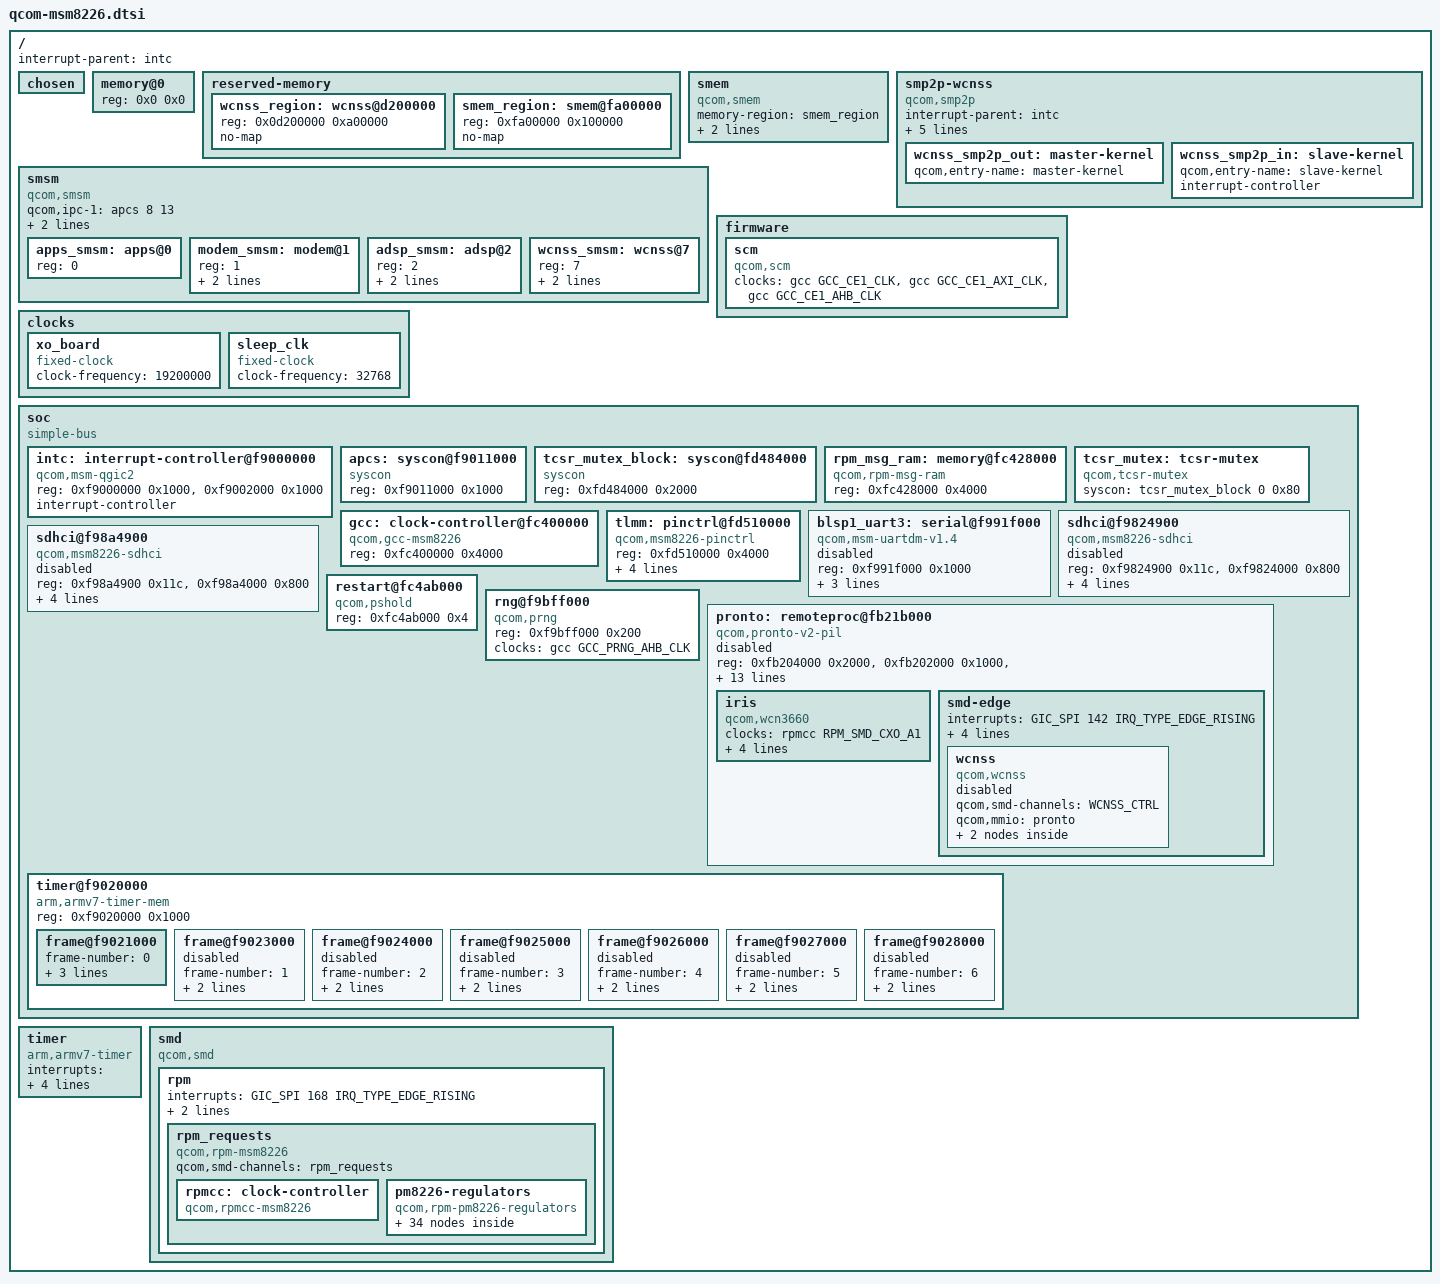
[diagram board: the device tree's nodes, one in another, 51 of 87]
// SPDX-License-Identifier: BSD-3-Clause
/*
 * Copyright (c) 2020, The Linux Foundation. All rights reserved.
 */

/dts-v1/;

#include <dt-bindings/interrupt-controller/arm-gic.h>
#include <dt-bindings/clock/qcom,gcc-msm8974.h>
#include <dt-bindings/clock/qcom,rpmcc.h>
#include <dt-bindings/gpio/gpio.h>

/ {
	#address-cells = <1>;
	#size-cells = <1>;
	interrupt-parent = <&intc>;

	chosen { };

	memory@0 {
		device_type = "memory";
		reg = <0x0 0x0>;
	};

	reserved-memory {
		#address-cells = <1>;
		#size-cells = <1>;
		ranges;

		wcnss_region: wcnss@d200000 {
			reg = <0x0d200000 0xa00000>;
			no-map;
		};

		smem_region: smem@fa00000 {
			reg = <0xfa00000 0x100000>;
			no-map;
		};
	};

	smem {
		compatible = "qcom,smem";

		memory-region = <&smem_region>;
		qcom,rpm-msg-ram = <&rpm_msg_ram>;

		hwlocks = <&tcsr_mutex 3>;
	};

	smp2p-wcnss {
		compatible = "qcom,smp2p";

		interrupt-parent = <&intc>;
		interrupts = <GIC_SPI 143 IRQ_TYPE_EDGE_RISING>;

		qcom,smem = <451>, <431>;
		qcom,ipc = <&apcs 8 18>;
		qcom,local-pid = <0>;
		qcom,remote-pid = <4>;

		wcnss_smp2p_out: master-kernel {
			qcom,entry-name = "master-kernel";

			#qcom,smem-state-cells = <1>;
		};

		wcnss_smp2p_in: slave-kernel {
			qcom,entry-name = "slave-kernel";

			interrupt-controller;
			#interrupt-cells = <2>;
		};
	};

	smsm {
		compatible = "qcom,smsm";

		#address-cells = <1>;
		#size-cells = <0>;

		qcom,ipc-1 = <&apcs 8 13>;
		qcom,ipc-2 = <&apcs 8 9>;
		qcom,ipc-3 = <&apcs 8 19>;

		apps_smsm: apps@0 {
			reg = <0>;

			#qcom,smem-state-cells = <1>;
		};

		modem_smsm: modem@1 {
			reg = <1>;
			interrupts = <GIC_SPI 26 IRQ_TYPE_EDGE_RISING>;

			interrupt-controller;
			#interrupt-cells = <2>;
		};

		adsp_smsm: adsp@2 {
			reg = <2>;
			interrupts = <GIC_SPI 157 IRQ_TYPE_EDGE_RISING>;

			interrupt-controller;
			#interrupt-cells = <2>;
		};

		wcnss_smsm: wcnss@7 {
			reg = <7>;
			interrupts = <GIC_SPI 144 IRQ_TYPE_EDGE_RISING>;

			interrupt-controller;
			#interrupt-cells = <2>;
		};
	};

	firmware {
		scm {
			compatible = "qcom,scm";
			clocks = <&gcc GCC_CE1_CLK>, <&gcc GCC_CE1_AXI_CLK>, <&gcc GCC_CE1_AHB_CLK>;
			clock-names = "core", "bus", "iface";
		};
	};

	clocks {
		xo_board: xo_board {
			compatible = "fixed-clock";
			#clock-cells = <0>;
			clock-frequency = <19200000>;
		};

		sleep_clk: sleep_clk {
			compatible = "fixed-clock";
			#clock-cells = <0>;
			clock-frequency = <32768>;
		};
	};

	soc: soc {
		compatible = "simple-bus";
		#address-cells = <1>;
		#size-cells = <1>;
		ranges;

		intc: interrupt-controller@f9000000 {
			compatible = "qcom,msm-qgic2";
			reg = <0xf9000000 0x1000>,
			      <0xf9002000 0x1000>;
			interrupt-controller;
			#interrupt-cells = <3>;
		};

		apcs: syscon@f9011000 {
			compatible = "syscon";
			reg = <0xf9011000 0x1000>;
		};

		tcsr_mutex_block: syscon@fd484000 {
			compatible = "syscon";
			reg = <0xfd484000 0x2000>;
		};

		rpm_msg_ram: memory@fc428000 {
			compatible = "qcom,rpm-msg-ram";
			reg = <0xfc428000 0x4000>;
		};

		tcsr_mutex: tcsr-mutex {
			compatible = "qcom,tcsr-mutex";
			syscon = <&tcsr_mutex_block 0 0x80>;

			#hwlock-cells = <1>;
		};

		gcc: clock-controller@fc400000 {
			compatible = "qcom,gcc-msm8226";
			reg = <0xfc400000 0x4000>;
			#clock-cells = <1>;
			#reset-cells = <1>;
			#power-domain-cells = <1>;
		};

		tlmm: pinctrl@fd510000 {
			compatible = "qcom,msm8226-pinctrl";
			reg = <0xfd510000 0x4000>;
			gpio-controller;
			#gpio-cells = <2>;
			gpio-ranges = <&tlmm 0 0 117>;
			interrupt-controller;
			#interrupt-cells = <2>;
			interrupts = <GIC_SPI 208 IRQ_TYPE_LEVEL_HIGH>;
		};

		blsp1_uart3: serial@f991f000 {
			compatible = "qcom,msm-uartdm-v1.4", "qcom,msm-uartdm";
			reg = <0xf991f000 0x1000>;
			interrupts = <GIC_SPI 109 IRQ_TYPE_LEVEL_HIGH>;
			clocks = <&gcc GCC_BLSP1_UART3_APPS_CLK>, <&gcc GCC_BLSP1_AHB_CLK>;
			clock-names = "core", "iface";
			status = "disabled";
		};

		sdhci@f9824900 {
			compatible = "qcom,msm8226-sdhci", "qcom,sdhci-msm-v4";
			reg = <0xf9824900 0x11c>, <0xf9824000 0x800>;
			reg-names = "hc_mem", "core_mem";
			interrupts = <GIC_SPI 123 IRQ_TYPE_LEVEL_HIGH>,
				     <GIC_SPI 138 IRQ_TYPE_LEVEL_HIGH>;
			interrupt-names = "hc_irq", "pwr_irq";
			clocks = <&gcc GCC_SDCC1_APPS_CLK>,
				 <&gcc GCC_SDCC1_AHB_CLK>,
				 <&xo_board>;
			clock-names = "core", "iface", "xo";
			status = "disabled";
		};

		sdhci@f98a4900 {
			compatible = "qcom,msm8226-sdhci", "qcom,sdhci-msm-v4";
			reg = <0xf98a4900 0x11c>, <0xf98a4000 0x800>;
			reg-names = "hc_mem", "core_mem";
			interrupts = <GIC_SPI 125 IRQ_TYPE_LEVEL_HIGH>,
				     <GIC_SPI 221 IRQ_TYPE_LEVEL_HIGH>;
			interrupt-names = "hc_irq", "pwr_irq";
			clocks = <&gcc GCC_SDCC2_APPS_CLK>,
				 <&gcc GCC_SDCC2_AHB_CLK>,
				 <&xo_board>;
			clock-names = "core", "iface", "xo";
			status = "disabled";
		};

		restart@fc4ab000 {
			compatible = "qcom,pshold";
			reg = <0xfc4ab000 0x4>;
		};

		rng@f9bff000 {
			compatible = "qcom,prng";
			reg = <0xf9bff000 0x200>;
			clocks = <&gcc GCC_PRNG_AHB_CLK>;
			clock-names = "core";
		};

		pronto: remoteproc@fb21b000 {
			compatible = "qcom,pronto-v2-pil", "qcom,pronto";
			reg = <0xfb204000 0x2000>, <0xfb202000 0x1000>, <0xfb21b000 0x3000>;
			reg-names = "ccu", "dxe", "pmu";

			memory-region = <&wcnss_region>;

			interrupts-extended = <&intc GIC_SPI 149 IRQ_TYPE_EDGE_RISING>,
					      <&wcnss_smp2p_in 0 IRQ_TYPE_EDGE_RISING>,
					      <&wcnss_smp2p_in 1 IRQ_TYPE_EDGE_RISING>,
					      <&wcnss_smp2p_in 2 IRQ_TYPE_EDGE_RISING>,
					      <&wcnss_smp2p_in 3 IRQ_TYPE_EDGE_RISING>;
			interrupt-names = "wdog", "fatal", "ready", "handover", "stop-ack";

			vddmx-supply = <&pm8226_l3>;
			vddcx-supply = <&pm8226_s1>;
			vddpx-supply = <&pm8226_l6>;

			qcom,smem-states = <&wcnss_smp2p_out 0>;
			qcom,smem-state-names = "stop";

			status = "disabled";

			iris {
				compatible = "qcom,wcn3660";

				clocks = <&rpmcc RPM_SMD_CXO_A1>;
				clock-names = "xo";

				vddxo-supply = <&pm8226_l10>;
				vddrfa-supply = <&pm8226_l24>;
				vddpa-supply = <&pm8226_l16>;
				vdddig-supply = <&pm8226_l24>;
			};

			smd-edge {
				interrupts = <GIC_SPI 142 IRQ_TYPE_EDGE_RISING>;

				qcom,ipc = <&apcs 8 17>;
				qcom,smd-edge = <6>;
				qcom,remote-pid = <4>;

				label = "pronto";

				wcnss {
					compatible = "qcom,wcnss";
					qcom,smd-channels = "WCNSS_CTRL";
					status = "disabled";

					qcom,mmio = <&pronto>;

					bt {
						compatible = "qcom,wcnss-bt";
					};

					wlan {
						compatible = "qcom,wcnss-wlan";

						interrupts = <GIC_SPI 145 IRQ_TYPE_EDGE_RISING>,
							     <GIC_SPI 146 IRQ_TYPE_EDGE_RISING>;
						interrupt-names = "tx", "rx";

						qcom,smem-states = <&apps_smsm 10>,
								   <&apps_smsm 9>;
						qcom,smem-state-names = "tx-enable",
									"tx-rings-empty";
					};
				};
			};
		};

		timer@f9020000 {
			compatible = "arm,armv7-timer-mem";
			reg = <0xf9020000 0x1000>;
			#address-cells = <1>;
			#size-cells = <1>;
			ranges;

			frame@f9021000 {
				frame-number = <0>;
				interrupts = <GIC_SPI 8 IRQ_TYPE_LEVEL_HIGH>,
					     <GIC_SPI 7 IRQ_TYPE_LEVEL_HIGH>;
				reg = <0xf9021000 0x1000>,
				      <0xf9022000 0x1000>;
			};

			frame@f9023000 {
				frame-number = <1>;
				interrupts = <GIC_SPI 9 IRQ_TYPE_LEVEL_HIGH>;
				reg = <0xf9023000 0x1000>;
				status = "disabled";
			};

			frame@f9024000 {
				frame-number = <2>;
				interrupts = <GIC_SPI 10 IRQ_TYPE_LEVEL_HIGH>;
				reg = <0xf9024000 0x1000>;
				status = "disabled";
			};

			frame@f9025000 {
				frame-number = <3>;
				interrupts = <GIC_SPI 11 IRQ_TYPE_LEVEL_HIGH>;
				reg = <0xf9025000 0x1000>;
				status = "disabled";
			};

			frame@f9026000 {
				frame-number = <4>;
				interrupts = <GIC_SPI 12 IRQ_TYPE_LEVEL_HIGH>;
				reg = <0xf9026000 0x1000>;
				status = "disabled";
			};

			frame@f9027000 {
				frame-number = <5>;
				interrupts = <GIC_SPI 13 IRQ_TYPE_LEVEL_HIGH>;
				reg = <0xf9027000 0x1000>;
				status = "disabled";
			};

			frame@f9028000 {
				frame-number = <6>;
				interrupts = <GIC_SPI 14 IRQ_TYPE_LEVEL_HIGH>;
				reg = <0xf9028000 0x1000>;
				status = "disabled";
			};
		};
	};

	timer {
		compatible = "arm,armv7-timer";
		interrupts = <GIC_PPI 2
				(GIC_CPU_MASK_RAW(15) | IRQ_TYPE_LEVEL_LOW)>,
			     <GIC_PPI 3
				(GIC_CPU_MASK_RAW(15) | IRQ_TYPE_LEVEL_LOW)>,
			     <GIC_PPI 4
				(GIC_CPU_MASK_RAW(15) | IRQ_TYPE_LEVEL_LOW)>,
			     <GIC_PPI 1
				(GIC_CPU_MASK_RAW(15) | IRQ_TYPE_LEVEL_LOW)>;
	};

	smd {
		compatible = "qcom,smd";

		rpm {
			interrupts = <GIC_SPI 168 IRQ_TYPE_EDGE_RISING>;
			qcom,ipc = <&apcs 8 0>;
			qcom,smd-edge = <15>;

			rpm_requests {
				compatible = "qcom,rpm-msm8226";
				qcom,smd-channels = "rpm_requests";

				rpmcc: clock-controller {
					compatible = "qcom,rpmcc-msm8226", "qcom,rpmcc";
					#clock-cells = <1>;
				};

				pm8226-regulators {
					compatible = "qcom,rpm-pm8226-regulators";

					pm8226_s1: s1 {};
					pm8226_s2: s2 {};
					pm8226_s3: s3 {};
					pm8226_s4: s4 {};
					pm8226_s5: s5 {};

					pm8226_l1: l1 {};
					pm8226_l2: l2 {};
					pm8226_l3: l3 {};
					pm8226_l4: l4 {};
					pm8226_l5: l5 {};
					pm8226_l6: l6 {};
					pm8226_l7: l7 {};
					pm8226_l8: l8 {};
					pm8226_l9: l9 {};
					pm8226_l10: l10 {};
					pm8226_l11: l11 {};
					pm8226_l12: l12 {};
					pm8226_l13: l13 {};
					pm8226_l14: l14 {};
					pm8226_l15: l15 {};
					pm8226_l16: l16 {};
					pm8226_l17: l17 {};
					pm8226_l18: l18 {};
					pm8226_l19: l19 {};
					pm8226_l20: l20 {};
					pm8226_l21: l21 {};
					pm8226_l22: l22 {};
					pm8226_l23: l23 {};
					pm8226_l24: l24 {};
					pm8226_l25: l25 {};
					pm8226_l26: l26 {};
					pm8226_l27: l27 {};
					pm8226_l28: l28 {};

					pm8226_lvs1: lvs1 {};
				};
			};
		};
	};
};
